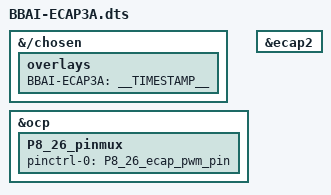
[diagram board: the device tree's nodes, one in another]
/*
 * Copyright (C) 2020 Deepak Khatri <deepaklorkhatri7@gmail.com>
 *
 * Virtual cape for BBAI ECAP3A
 *
 * This program is free software; you can redistribute it and/or modify
 * it under the terms of the GNU General Public License version 2 as
 * published by the Free Software Foundation.
 */

/dts-v1/;
/plugin/;

/*
* Helper to show loaded overlays under: /proc/device-tree/chosen/overlays/
*/
&{/chosen} {
    overlays {
        BBAI-ECAP3A = __TIMESTAMP__;
    };
};

/*
 * Update the default pinmux of the pins.
 * See these files for the phandles (&P9_* & &P8_*)
 * https://github.com/lorforlinux/BeagleBoard-DeviceTrees/blob/compatibility/src/arm/am335x-bone-common-univ.dtsi
 * https://github.com/lorforlinux/BeagleBoard-DeviceTrees/blob/compatibility/src/arm/am572x-bone-common-univ.dtsi
 */
&ocp {
	P8_26_pinmux { pinctrl-0 = <&P8_26_ecap_pwm_pin>; };	/* eCAP3_in_PWM3_out */
};

/*
 * See these files for the phandles (&bone_*) and other bone bus nodes
 * https://github.com/lorforlinux/BeagleBoard-DeviceTrees/blob/compatibility/src/arm/bbai-bone-buses.dtsi
 * https://github.com/lorforlinux/BeagleBoard-DeviceTrees/blob/compatibility/src/arm/bbb-bone-buses.dtsi
 */
&ecap2 {
	status = "okay";
};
